# DSI_PLL_controller register map
Vendor: Texas Instruments
Peripheral module from a debugger description file (folder omap34xx).
Registers are 32-bit, access per field, reset 0x0 unless marked. A register's access mark holds for its fields unless they carry their own. Offsets are as the file gives them; lines under a group give offsets from that group; [hi:lo] are bit positions; {n}, {i} and the like mark numbered series; 'fields as' and 'values as' point back to an identical list; <NAME> marks a mode.

## DSI_PLL_Controller
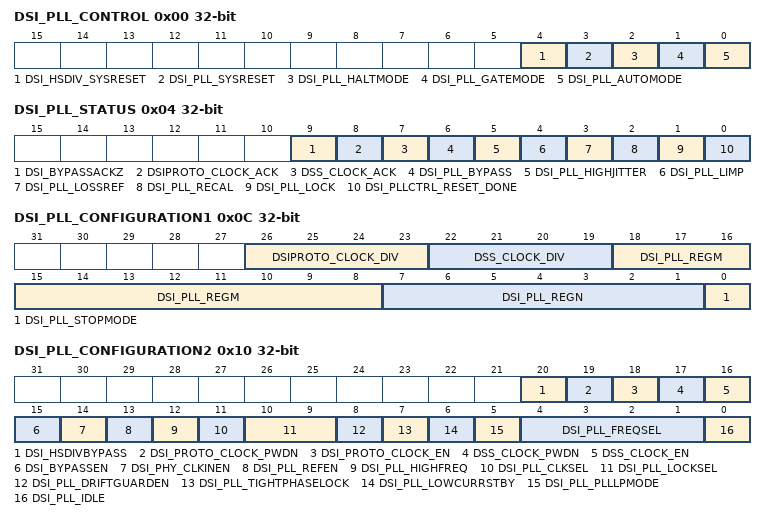
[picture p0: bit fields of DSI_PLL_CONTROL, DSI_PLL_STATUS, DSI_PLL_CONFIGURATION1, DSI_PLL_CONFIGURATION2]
0x00 DSI_PLL_CONTROL — This register controls the PLL reset/power and modes
  [4] DSI_HSDIV_SYSRESET rw — Force HSDIVIDER SYSRESET
    0=HSDIVIDER SYSRESET controlled by power FSM; 1=HSDIVIDER SYSRESET forced active
  [3] DSI_PLL_SYSRESET rw — Force ADPLLV2 SYSRESET
    0=PLL SYSRESET controlled by power FSM; 1=PLL SYSRESET forced active
  [2] DSI_PLL_HALTMODE rw — Allow PLL to be halted if no activity
    0=PLL will not be halted; 1=PLL will be halted based on activity
  [1] DSI_PLL_GATEMODE rw — Allow PLL clock gating for power saving
    0=CLKIN4DDR on; 1=CLKIN4DDR gated by DSI Protocol Engine activity
  [0] DSI_PLL_AUTOMODE rw — Automatic update mode.If this bit is set then the configuration updates will be synchronized to DISPC_UPDATE_SYNC.If this bit is clear configuration updates will be done immediately.
    0=Manual mode; 1=Automatic mode
0x04 DSI_PLL_STATUS ro — This register contains the status information
  [9] DSI_BYPASSACKZ — State of bypass mode on PHY and HSDIVIDER
    0=DSI_PHY and HSDIVIDER have switched to using the bypass clocks; 1=PLL outputs are still being used by DSI_PHY or HSDIVIDER
  [8] DSIPROTO_CLOCK_ACK — Acknowledge for enable of DSI Protocol Engine clockVerify the status before selecting this source in the DSI Protocol Engine clock mux
    0=DSI Protocol Engine clock inactive; 1=DSI Protocol Engine clock active
  [7] DSS_CLOCK_ACK — Acknowledge for enable of DSS clockVerify the status before selecting this source in the DSS clock multiplexer
    0=DSS clock inactive; 1=DSS clock active
  [6] DSI_PLL_BYPASS — DSI PLL Bypass status
    0=PLL not bypassing; 1=PLL bypass
  [5] DSI_PLL_HIGHJITTER — DSI PLL High Jitter status
    0=PLL in normal jitter condition; 1=PLL in high jitter condition: Phase error > 24% (TIGHTPHASELOCK = 0) Phase error > 12%(TIGHTPHASELOCK = 1)
  [4] DSI_PLL_LIMP — DSI PLL Limp status
    0=LIMP mode inactive; 1=LIMP mode active
  [3] DSI_PLL_LOSSREF — DSI PLL Reference Loss status
    0=Reference input active; 1=Reference input inactive
  [2] DSI_PLL_RECAL — DSI PLL re-calibration statusIf this bit is active, the PLL must be recalibrated
    0=Recalibration is not required; 1=Recalibration is required
  [1] DSI_PLL_LOCK — DSI PLL Lock statusSee the programming guide for the use of this bit
    0=PLL is not locked; 1=PLL is locked
  [0] DSI_PLLCTRL_RESET_DONE — DSI PLL Controller reset done status
    0=Reset is in progress; 1=Reset has completed
0x08 DSI_PLL_GO — This register contains the GO bit
  [0] DSI_PLL_GO rw — Request (re-)locking sequence of the PLL.If the AutoMode bit is set, then this will be deferred until DISPC_UPDATE_SYNC goes active
    0=No pending action; 1=Request PLL (re-)locking/locking pending
0x0C DSI_PLL_CONFIGURATION1 — This register contains the latched PLL and HSDIVDER configuration bits
  [26:23] DSIPROTO_CLOCK_DIV rw — Divider value for DSI Protocol Engine clock sourceREGM4
  [22:19] DSS_CLOCK_DIV rw — Divider value for DSS clock sourceREGM3
  [18:8] DSI_PLL_REGM rw — M Divider for PLL
  [7:1] DSI_PLL_REGN rw — N Divider for PLL (Reference)
  [0] DSI_PLL_STOPMODE rw
    0=STOPMODE is not selected; 1=STOPMODE is selected
0x10 DSI_PLL_CONFIGURATION2 — This register contains the unlatched PLL and HSDIVDER configuration bits These bits are 'shadowed' when automatic mode is selected
  [20] DSI_HSDIVBYPASS rw — Forces HSDIVIDER to bypass mode
    0=HSDIVIDER in normal operation. Bypass controlled by PLL.; 1=HSDIVIDER is forced to bypass mode
  [19] DSI_PROTO_CLOCK_PWDN rw — Power down for DSI Protocol Engine clock source
    0=DSI Protocol Engine clock divider is active; 1=DSI Protocol Engine clock divider is powered down
  [18] DSI_PROTO_CLOCK_EN rw — Enable for DSI Protocol Engine clock source
    0=DSI Protocol Engine clock divider is disabled; 1=DSI Protocol Engine clock divider is enabled
  [17] DSS_CLOCK_PWDN rw — Power down for DSS clock source
    0=DSS clock divider is active; 1=DSS clock divider is powered down
  [16] DSS_CLOCK_EN rw — Enable for DSS clock source
    0=DSS clock divider is disabled; 1=DSS clock divider is enabled
  [15] DSI_BYPASSEN rw — Selects DSS functional clock as CLKIN4DDR source
    0=PLL controls CLKIN4DDR source: PLL DCO if PLL is locked DSS functional clock if not locked; 1=Force DSS functional clock to be used as CLKIN4DDR source
  [14] DSI_PHY_CLKINEN rw — CLKIN4DDR control
    0=CLKIN4DDR is disabled; 1=CLKIN4DDR is enabled
  [13] DSI_PLL_REFEN rw — PLL reference clock control
    0=PLL reference clock disabled; 1=PLL reference clock enabled
  [12] DSI_PLL_HIGHFREQ rw — Enables a division of pixel clock by 2 before input to the PLLRequired for pixel clock frequencies above 32 MHz (21 MHZ if N = 0)
    0=Pixel clock is not divided; 1=Pixel clock is divided by 2
  [11] DSI_PLL_CLKSEL rw — Reference clock selection
    0=Selects DSS2_ALWON_FCLK as PLL reference clock; 1=Selects Pixel Clock (PCLKFREE) as PLL reference clock
  [10:9] DSI_PLL_LOCKSEL rw — Selects the lock criteria for the PLL
    0=Phase Lock criteria depends on setting of DSI_PLL_TIGHTPHASELOCK bit; 1=Frequency lock; 2=Spare
  [8] DSI_PLL_DRIFTGUARDEN rw
    0=Only RECAL flag is asserted in case of temperature drift. The programmer should take appropriate action.; 1=Temperature drift will initiate automatic recalibration. RECAL flag will be asserted while this is taking place.
  [7] DSI_PLL_TIGHTPHASELOCK rw — DSI PLL Phase Lock criteriaIf this bit is set, the phase lock tolerance is reduced
    0=Normal phase lock criteria Phase error lower than 6.4 %; 1=Tightened phase lock criteria Phase error lower than 3.2 %
  [6] DSI_PLL_LOWCURRSTBY rw — PLL LOW CURRENT STANDBY
    0=LOWCURRSTBY is not selected; 1=LOWCURRSTBY is selected
  [5] DSI_PLL_PLLLPMODE rw — Select the power/performance of the PLL
    0=Full performance, minimized jitter; 1=Reduced power, increased jitter
  [4:1] DSI_PLL_FREQSEL rw — PLL internal reference frequency range selection
    3=0.75MHz to 1.0MHz; 4=1.0MHz to 1.25MHz; 5=1.25MHz to 1.5MHz; 6=1.5MHz to 1.75MHz; 7=1.75MHz to 2.1MHz; 11=7.5MHz to 10MHz; 12=10MHz to 12.5MHz; 13=12.5MHz to 15MHz; 14=15MHz to 17.5MHz; 15=17.5MHz to 21MHz
  [0] DSI_PLL_IDLE rw
    0=IDLE is not selected; 1=IDLE is selected
